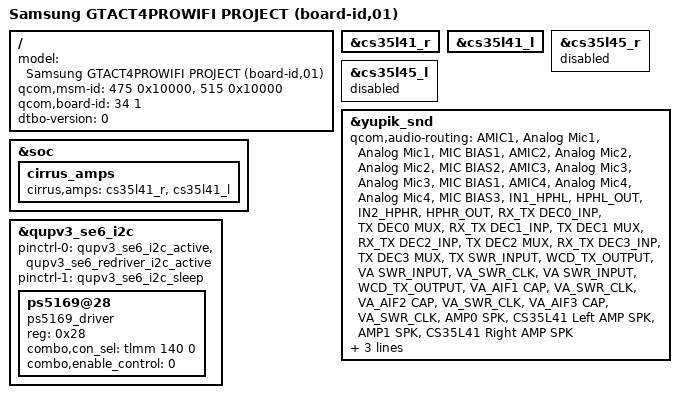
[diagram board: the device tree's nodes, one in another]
/* Copyright (c) 2021, The Linux Foundation. All rights reserved.
 *
 * This program is free software; you can redistribute it and/or modify
 * it under the terms of the GNU General Public License version 2 and
 * only version 2 as published by the Free Software Foundation.
 *
 * This program is distributed in the hope that it will be useful,
 * but WITHOUT ANY WARRANTY; without even the implied warranty of
 * MERCHANTABILITY or FITNESS FOR A PARTICULAR PURPOSE.  See the
 * GNU General Public License for more details.
 */

#include "../../yupik-sec-common.dtsi"

#include "../yupik-sec-gtactpro-common.dtsi"
#include "../yupik-sec-gtactpro-pinctrl-common.dtsi"
#include "../yupik-sec-gtactprowifi-sensor-r01.dtsi"
#include "../yupik-sec-gtactprowifi-sensor-pinctrl-r01.dtsi"
#include "./yupik-sec-gtact4prowifi-pm-common.dtsi"
#include "../yupik-sec-gtact4pro-input-common.dtsi"
#include "./yupik-sec-gtact4prowifi-wlan-common.dtsi"
#include "./yupik-sec-gtact4prowifi-pinctrl-r01.dtsi"
#include "../yupik-sec-gtact4pro-audio-common.dtsi"
#include "../yupik-sec-gtact4pro-audio-pinctrl-common.dtsi"
#include "./yupik-sec-gtact4pro-camera-sensor-common.dtsi"
#include "./yupik-sec-gtact4prowifi-bluetooth-common.dtsi"

/ {
	model = "Samsung GTACT4PROWIFI PROJECT (board-id,01)";
	qcom,msm-id = <475 0x10000>, <515 0x10000>;
	qcom,board-id = <34 1>;
	dtbo-version = <0>;
};

&cs35l41_r {
	status = "okay";
};
&cs35l41_l{
	status = "okay";
};
&cs35l45_r {
	status = "disable";
};
&cs35l45_l{
	status = "disable";
};

&yupik_snd {
	qcom,audio-routing =
		"AMIC1", "Analog Mic1",
		"Analog Mic1", "MIC BIAS1",
		"AMIC2", "Analog Mic2",
		"Analog Mic2", "MIC BIAS2",
		"AMIC3", "Analog Mic3",
		"Analog Mic3", "MIC BIAS1",
		"AMIC4", "Analog Mic4",
		"Analog Mic4", "MIC BIAS3",
		"IN1_HPHL", "HPHL_OUT",
		"IN2_HPHR", "HPHR_OUT",
		"RX_TX DEC0_INP", "TX DEC0 MUX",
		"RX_TX DEC1_INP", "TX DEC1 MUX",
		"RX_TX DEC2_INP", "TX DEC2 MUX",
		"RX_TX DEC3_INP", "TX DEC3 MUX",
		"TX SWR_INPUT", "WCD_TX_OUTPUT",
		"VA SWR_INPUT", "VA_SWR_CLK",
		"VA SWR_INPUT", "WCD_TX_OUTPUT",
		"VA_AIF1 CAP", "VA_SWR_CLK",
		"VA_AIF2 CAP", "VA_SWR_CLK",
		"VA_AIF3 CAP", "VA_SWR_CLK",
		"AMP0 SPK", "CS35L41 Left AMP SPK",
		"AMP1 SPK", "CS35L41 Right AMP SPK";
	qcom,codec-conf = <0x12>; /* CS35L41 stereo*/
	cirrus_amp_link = "cs35l41.18-0043", "cs35l41-pcm",
		"cs35l41.18-0041", "cs35l41-pcm";
};

&soc {
	cirrus_amps {
		cirrus,amps = <&cs35l41_r &cs35l41_l>;
	};
};

&qupv3_se6_i2c {
	status = "ok";

	pinctrl-names = "default", "sleep";
	pinctrl-0 = <&qupv3_se6_i2c_active &qupv3_se6_redriver_i2c_active>;
	pinctrl-1 = <&qupv3_se6_i2c_sleep>;

	ps5169@28 {
		compatible = "ps5169_driver";
		reg = <0x28>;
		combo,con_sel = <&tlmm 140 0>;
		combo,enable_control = <0>;
	};
};
